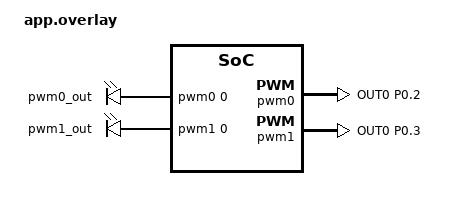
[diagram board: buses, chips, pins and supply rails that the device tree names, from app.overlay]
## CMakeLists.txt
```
# SPDX-License-Identifier: Apache-2.0

cmake_minimum_required(VERSION 3.20.0)
find_package(Zephyr REQUIRED HINTS $ENV{ZEPHYR_BASE})
project(observer)

target_sources(app PRIVATE
  src/main.c
  src/comms.c
  src/servo.c 
)
```

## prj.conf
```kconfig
CONFIG_BT=y
CONFIG_BT_PERIPHERAL=y
CONFIG_BT_ZEPHYR_NUS=y
CONFIG_BT=y
CONFIG_BT_OBSERVER=y
CONFIG_BT_EXT_ADV=n
CONFIG_BT=y
CONFIG_BT_PERIPHERAL=y
CONFIG_BT_ZEPHYR_NUS=y
CONFIG_BT_DEVICE_NAME="mobile_node"
CONFIG_PWM=y
CONFIG_PINCTRL=y
CONFIG_JSON_LIBRARY=y
CONFIG_JSON_LIBRARY_FP_SUPPORT=y

# Increase ATT MTU to allow larger packets (max 247 bytes for NUS)
CONFIG_BT_L2CAP_TX_MTU=247
CONFIG_BT_BUF_ACL_RX_SIZE=251
CONFIG_BT_BUF_ACL_TX_SIZE=251
CONFIG_BT_GATT_CLIENT=y
CONFIG_CBPRINTF_FP_SUPPORT=y
```

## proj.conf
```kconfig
CONFIG_BT=y
CONFIG_BT_PERIPHERAL=y
CONFIG_BT_ZEPHYR_NUS=y
CONFIG_BT=y
CONFIG_BT_OBSERVER=y
CONFIG_BT_EXT_ADV=n
CONFIG_BT=y
CONFIG_BT_PERIPHERAL=y
CONFIG_BT_ZEPHYR_NUS=y
CONFIG_BT_DEVICE_NAME="mobile_node"
CONFIG_PWM=y
CONFIG_PINCTRL=y
CONFIG_JSON_LIBRARY=y
CONFIG_SHELL_BACKEND_SERIAL=y
CONFIG_UART_CONSOLE=y
CONFIG_SHELL=y
```

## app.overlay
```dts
#include <zephyr/dt-bindings/pwm/pwm.h>
#include <zephyr/dt-bindings/pinctrl/nrf-pinctrl.h>

/ {
    pwmleds: pwmleds {
        compatible = "pwm-leds";

        pwm0_out: pwm0_out {
            pwms = <&pwm0 0 PWM_MSEC(20) PWM_POLARITY_NORMAL>;
        };

        pwm1_out: pwm1_out {
            pwms = <&pwm1 0 PWM_MSEC(20) PWM_POLARITY_NORMAL>;
        };
    };
};

&pinctrl {
    pwm0_default: pwm0_default {
        group1 {
            /* PWM0 output on P0.13 - change this pin */
            psels = <NRF_PSEL(PWM_OUT0, 0, 2)>;
        };
    };

    pwm0_sleep: pwm0_sleep {
        group1 {
            psels = <NRF_PSEL(PWM_OUT0, 0, 2)>;
            low-power-enable;
        };
    };

    pwm1_default: pwm1_default {
        group1 {
            /* PWM1 output on P0.14 - change this pin */
            psels = <NRF_PSEL(PWM_OUT0, 0, 3)>;
        };
    };

    pwm1_sleep: pwm1_sleep {
        group1 {
            psels = <NRF_PSEL(PWM_OUT0, 0, 3)>;
            low-power-enable;
        };
    };
};

&pwm0 {
    status = "okay";
    pinctrl-0 = <&pwm0_default>;
    pinctrl-1 = <&pwm0_sleep>;
    pinctrl-names = "default", "sleep";
};

&pwm1 {
    status = "okay";
    pinctrl-0 = <&pwm1_default>;
    pinctrl-1 = <&pwm1_sleep>;
    pinctrl-names = "default", "sleep";
};
```

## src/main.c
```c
/*********************************** */
/*              main.c               */
/*********************************** */
/* Authors                           */
/* Sidney Neil 47441952              */
/* Fiachra Richards  47450271        */
/*********************************** */

/********* Include Libraries ******* */
#include <zephyr/sys/printk.h>
#include <zephyr/bluetooth/bluetooth.h>
#include <zephyr/kernel.h>

#include "comms.h"
#include "servo.h"
/********************************* */

/*********** Global Defines ********** */

/* Thread configuration */
#define STACK_SIZE       2048
#define COMMS_PRIORITY   5
#define SERVO_PRIORITY 5

/* Thread entry functions defined in their respective modules */
extern void comms_thread(void *a, void *b, void *c);
extern void servo_thread(void* a, void* b, void* c);

/* Stack areas for sensing and communication threads */
K_THREAD_STACK_DEFINE(comms_stack, STACK_SIZE);
K_THREAD_STACK_DEFINE(servo_stack, STACK_SIZE);

/* Thread control blocks */
static struct k_thread comms_thread_data;
static struct k_thread servo_thread_data;

int main(void)
{
    /* Start the communications thread for sending collected data over BLE */
    k_thread_create(&comms_thread_data, comms_stack, K_THREAD_STACK_SIZEOF(comms_stack),
                    comms_thread, NULL, NULL, NULL, COMMS_PRIORITY, 0, K_NO_WAIT);

    k_thread_create(&servo_thread_data, servo_stack, K_THREAD_STACK_SIZEOF(servo_stack),
                    servo_thread, NULL, NULL, NULL, SERVO_PRIORITY, 0, K_NO_WAIT);

    return 0;
}
```

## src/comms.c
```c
/*********************************** */
/*             comms.c               */
/*********************************** */
/* Authors                           */
/* Sidney Neil 47441952              */
/* Fiachra Richards  47450271        */
/*********************************** */

/********* Include Libraries ******* */
#include <zephyr/kernel.h>
#include <zephyr/bluetooth/bluetooth.h>
#include <zephyr/bluetooth/services/nus.h>
#include <zephyr/data/json.h>
#include "comms.h"
#include "servo.h"
/********************************* */

/*********** Global Defines ********** */

/* BLE advertising configuration */
#define DEVICE_NAME       CONFIG_BT_DEVICE_NAME
#define DEVICE_NAME_LEN   (sizeof(DEVICE_NAME) - 1)
#define MESSAGE_WAIT_TIME 1

/* Work queue item used to restart advertising after disconnection */
static struct k_work adv_wq;

int init_comms(void);
int send_comms(int8_t *data, uint16_t len);
static void adv_wq_handler(struct k_work *work);

static const struct json_obj_descr angle_descr[] = {
    JSON_OBJ_DESCR_PRIM(struct angle_struct, theta, JSON_TOK_FLOAT_FP),
    JSON_OBJ_DESCR_PRIM(struct angle_struct, phi, JSON_TOK_FLOAT_FP),
};

/* Primary BLE advertising data */
static const struct bt_data ad[] = {
    BT_DATA_BYTES(BT_DATA_FLAGS, (BT_LE_AD_GENERAL | BT_LE_AD_NO_BREDR)),
    BT_DATA(BT_DATA_NAME_COMPLETE, DEVICE_NAME, DEVICE_NAME_LEN),
};

/* Scan response data advertising the Nordic UART Service UUID */
static const struct bt_data sd[] = {
    BT_DATA_BYTES(BT_DATA_UUID128_ALL, BT_UUID_NUS_SRV_VAL),
};

/* Callback triggered when NUS notifications are enabled or disabled */
static void notif_enabled(bool enabled, void *ctx)
{
    ARG_UNUSED(ctx);

    printk("%s() - %s\n", __func__, (enabled ? "Enabled" : "Disabled"));
}

/* Callback triggered when data is received over NUS */
static void received(struct bt_conn *conn, const void *data, uint16_t len, void *ctx)
{
    ARG_UNUSED(conn);
    ARG_UNUSED(ctx);

    struct angle_struct angles = {0};

    char buf[len + 1];
    memcpy(buf, data, len);
    buf[len] = '\0';
    int ret = json_obj_parse(buf, len, angle_descr, ARRAY_SIZE(angle_descr), &angles);
    if (ret >= 0) {
        k_msgq_put(&servo_msgq, &angles, K_NO_WAIT);
    }

    printk("%s\n", (char *)data);
}

/* Nordic UART Service callback registration */
struct bt_nus_cb nus_listener = {
    .notif_enabled = notif_enabled,
    .received = received,
};

/*
 * Initialises BLE communication.
 * Registers the NUS callbacks and starts connectable BLE advertising.
 */
int init_comms(void)
{
    int err;

    err = bt_nus_cb_register(&nus_listener, NULL);
	if (err) {
		printk("Failed to register NUS callback: %d\n", err);
		return err;
	}

	err = bt_enable(NULL);
	if (err) {
		printk("Failed to enable bluetooth: %d\n", err);
		return err;
	}

	err = bt_le_adv_start(BT_LE_ADV_CONN_FAST_1, ad, ARRAY_SIZE(ad), sd, ARRAY_SIZE(sd));
	if (err) {
		printk("Failed to start advertising: %d\n", err);
		return err;
	}

    printk("Advertising as %s...\n", DEVICE_NAME);
    return 0;
}

/*
 * Communication thread.
 * Waits for RSSI data from the sensor/scanner queue and sends it over BLE.
 */
void comms_thread(void *a, void *b, void *c)
{
    int8_t rssi_table[13];

    init_comms();

    while (1) {
        k_sleep(K_MSEC(100));
    }
}

/* Restarts BLE advertising after a connection is lost */
static void adv_wq_handler(struct k_work *work)
{
    int err = bt_le_adv_start(BT_LE_ADV_CONN_FAST_1, ad, ARRAY_SIZE(ad), sd, ARRAY_SIZE(sd));
    if (err) {
        printk("Failed to restart advertising (err %d)\n", err);
    } else {
        printk("Advertising restarted\n");
    }
}

/* Handles BLE disconnection events */
static void on_disconnected(struct bt_conn *conn, uint8_t reason)
{
    printk("Disconnected (reason %d)\n", reason);
    k_work_submit(&adv_wq);
}

/* Handles BLE connection events */
static void on_connected(struct bt_conn *conn, uint8_t err)
{
    if (err) {
        printk("Connection failed (err %d)\n", err);
        return;
    }

    printk("Connected\n");
}

/* Register BLE connection callbacks */
BT_CONN_CB_DEFINE(conn_callbacks) = {
    .connected = on_connected,
    .disconnected = on_disconnected,
};
```

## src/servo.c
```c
#include <stdio.h>
#include <zephyr/kernel.h>
#include <zephyr/drivers/gpio.h>
#include <zephyr/drivers/pwm.h>
#include "servo.h"

static const struct pwm_dt_spec pwm_spec_0 =
    PWM_DT_SPEC_GET(DT_NODELABEL(pwm0_out));

static const struct pwm_dt_spec pwm_spec_1 =
    PWM_DT_SPEC_GET(DT_NODELABEL(pwm1_out));

K_MSGQ_DEFINE(servo_msgq, sizeof(struct angle_struct), 1, 4);

/* Maps 0-180 degrees to 1000-2000us pulse width, returned in nanoseconds */
static uint32_t angle_to_pulse_ns(float theta)
{
    if (theta < 0.0f) theta = 0.0f;
    if (theta > 180.0f) theta = 180.0f;

    float pulse_us = 700.0f + (theta / 180.0f) * 2000.0f;
    return (uint32_t)(pulse_us * 1000.0f);
}

static void drive_to_theta(float theta, float phi)
{
    uint32_t pan_pulse_ns  = angle_to_pulse_ns(theta);
    uint32_t tilt_pulse_ns = angle_to_pulse_ns(phi);

    printk("%d, %d\n", pan_pulse_ns, tilt_pulse_ns);

    pwm_set_pulse_dt(&pwm_spec_0, pan_pulse_ns);
    pwm_set_pulse_dt(&pwm_spec_1, tilt_pulse_ns);
}

void servo_thread(void *a, void *b, void *c)
{
    if (!pwm_is_ready_dt(&pwm_spec_0)) {
        printk("PWM0 not ready\n");
        return;
    }

    if (!pwm_is_ready_dt(&pwm_spec_1)) {
        printk("PWM1 not ready\n");
        return;
    }

    struct angle_struct angles = {0};

    while (1) {
        k_msgq_get(&servo_msgq, &angles, K_FOREVER);
        drive_to_theta(angles.theta, angles.phi);
        k_sleep(K_MSEC(100));
    }
}
```

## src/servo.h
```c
#ifndef SERVO_H
#define SERVO_H

#include <zephyr/kernel.h>

/* Thread entry point for scanning known BLE beacons and collecting RSSI data */
void servo_thread(void* a, void* b, void* c);

/* Shared queue containing the latest RSSI table for the communications thread */
extern struct k_msgq servo_msgq;
struct angle_struct {
    float theta;
    float phi;
};

#endif /* SENSOR_H */
```
